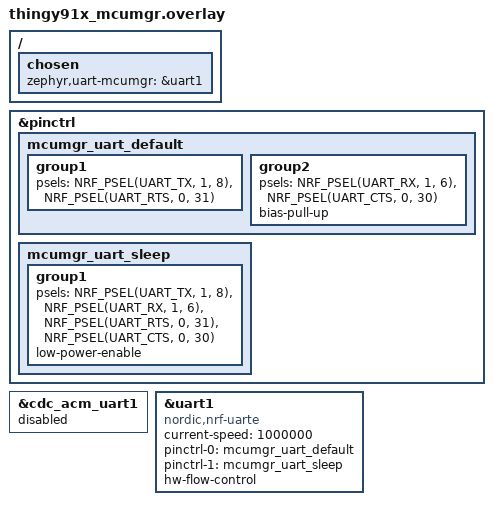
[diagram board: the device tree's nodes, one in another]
/*
 * Copyright (c) 2023 Nordic Semiconductor ASA
 *
 * SPDX-License-Identifier: LicenseRef-Nordic-5-Clause
 */

&pinctrl {
	mcumgr_uart_default: mcumgr_uart_default {
		group1 {
			psels = <NRF_PSEL(UART_TX, 1, 8)>,
				<NRF_PSEL(UART_RTS, 0, 31)>;
		};
		group2 {
			psels = <NRF_PSEL(UART_RX, 1, 6)>,
				<NRF_PSEL(UART_CTS, 0, 30)>;
			bias-pull-up;
		};
	};

	mcumgr_uart_sleep: mcumgr_uart_sleep {
		group1 {
			psels = <NRF_PSEL(UART_TX, 1, 8)>,
				<NRF_PSEL(UART_RX, 1, 6)>,
				<NRF_PSEL(UART_RTS, 0, 31)>,
				<NRF_PSEL(UART_CTS, 0, 30)>;
			low-power-enable;
		};
	};

};

&cdc_acm_uart1 {
	status = "disabled";
};

&uart1 {
	compatible = "nordic,nrf-uarte";
	current-speed = <1000000>;
	status = "okay";
	pinctrl-0 = <&mcumgr_uart_default>;
	pinctrl-1 = <&mcumgr_uart_sleep>;
	pinctrl-names = "default", "sleep";
	hw-flow-control;
};

/ {
        chosen {
                zephyr,uart-mcumgr = &uart1;
        };
};
